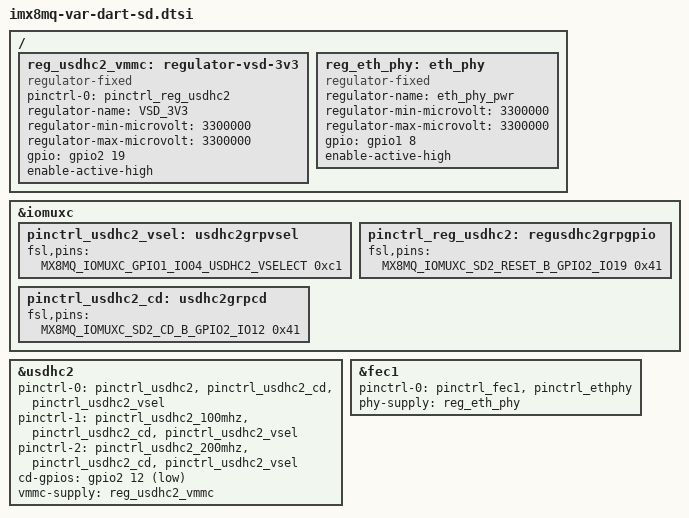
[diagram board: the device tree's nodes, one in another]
// SPDX-License-Identifier: (GPL-2.0 OR MIT)
/*
 * Copyright 2017 NXP
 * Copyright 2018-2020 Variscite Ltd.
 */

/ {
	reg_usdhc2_vmmc: regulator-vsd-3v3 {
		pinctrl-names = "default";
		pinctrl-0 = <&pinctrl_reg_usdhc2>;
		compatible = "regulator-fixed";
		regulator-name = "VSD_3V3";
		regulator-min-microvolt = <3300000>;
		regulator-max-microvolt = <3300000>;
		gpio = <&gpio2 19 GPIO_ACTIVE_HIGH>;
		enable-active-high;
	};

	reg_eth_phy: eth_phy {
		compatible = "regulator-fixed";
		regulator-name = "eth_phy_pwr";
		regulator-min-microvolt = <3300000>;
		regulator-max-microvolt = <3300000>;
		gpio = <&gpio1 8 GPIO_ACTIVE_HIGH>;
		enable-active-high;
	};
};

/* SD card voltage select pin */
&iomuxc {
	pinctrl_usdhc2_vsel: usdhc2grpvsel {
		fsl,pins = <
			MX8MQ_IOMUXC_GPIO1_IO04_USDHC2_VSELECT	0xc1
		>;
	};
	pinctrl_reg_usdhc2: regusdhc2grpgpio {
		fsl,pins = <
			MX8MQ_IOMUXC_SD2_RESET_B_GPIO2_IO19		0x41
		>;
	};
	pinctrl_usdhc2_cd: usdhc2grpcd {
		fsl,pins = <
			MX8MQ_IOMUXC_SD2_CD_B_GPIO2_IO12		0x41
		>;
	};
};

/* SD card */
&usdhc2 {
	pinctrl-names = "default", "state_100mhz", "state_200mhz";
	pinctrl-0 = <&pinctrl_usdhc2>, <&pinctrl_usdhc2_cd>, <&pinctrl_usdhc2_vsel>;
	pinctrl-1 = <&pinctrl_usdhc2_100mhz>, <&pinctrl_usdhc2_cd>, <&pinctrl_usdhc2_vsel>;
	pinctrl-2 = <&pinctrl_usdhc2_200mhz>, <&pinctrl_usdhc2_cd>, <&pinctrl_usdhc2_vsel>;
	cd-gpios = <&gpio2 12 GPIO_ACTIVE_LOW>;
	vmmc-supply = <&reg_usdhc2_vmmc>;
	status = "okay";
};

&fec1 {
	pinctrl-names = "default";
	pinctrl-0 = <&pinctrl_fec1>, <&pinctrl_ethphy>;
	phy-supply = <&reg_eth_phy>;
};
